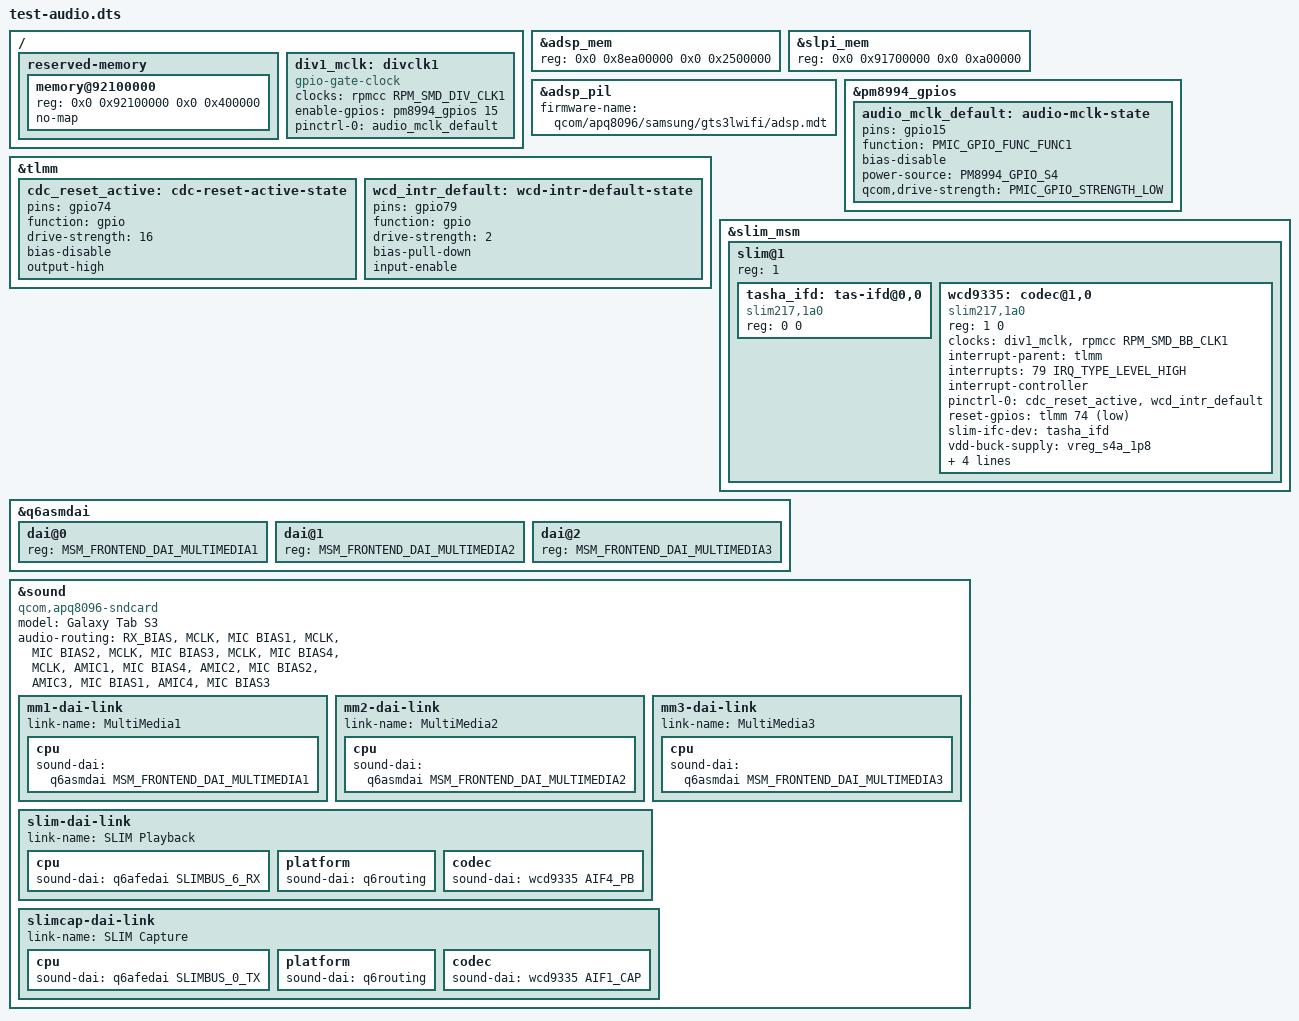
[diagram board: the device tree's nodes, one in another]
// SPDX-License-Identifier: BSD-3-Clause
/*
 * Audio test, stage 1: ADSP + WCD9335 (headphones and microphones).
 * Built on the Venus test DT.
 *
 * - ADSP: Samsung's signed firmware from the modem partition
 *   (image/adsp.mdt + .b00-.b09, ADSP.8996.2.7.1.C1-00013). Its segments are
 *   relocatable and span 0x2100000 bytes, more than msm8996.dtsi's 27 MB
 *   adsp_mem, so adsp_mem grows to the start of gpu_mem. SLPI (unused for
 *   now) moves into the stock peripheral_region tail at 0x91700000, which
 *   the board DTS reserves.
 * - WCD9335 on SLIMbus like apq8096-db820c / msm8996-xiaomi-common, with the
 *   Samsung wiring from the stock DT: reset TLMM 74 (wcd_gpio_ctrl
 *   qcom,cdc-rst-n-gpio), interrupt TLMM 79 (wcd9xxx-irq gpio-connect, one
 *   line), MCLK 9.6 MHz from PM8994 GPIO 15 function 1 (audio-ref-clk,
 *   RPM div_clk1), all supplies PM8994 S4 1.8 V.
 * - Speakers sit behind four Richtek RT5508 amplifiers on I2S (stage 2).
 */

#include <dt-bindings/sound/qcom,q6afe.h>
#include <dt-bindings/sound/qcom,q6asm.h>
#include <dt-bindings/sound/qcom,wcd9335.h>
#include "test-venus.dts"

/ {
	reserved-memory {
		/delete-node/ memory@91700000;

		/* rest of the stock peripheral_region after slpi_mem */
		memory@92100000 {
			reg = <0x0 0x92100000 0x0 0x400000>;
			no-map;
		};
	};

	div1_mclk: divclk1 {
		compatible = "gpio-gate-clock";
		clocks = <&rpmcc RPM_SMD_DIV_CLK1>;
		#clock-cells = <0>;
		enable-gpios = <&pm8994_gpios 15 GPIO_ACTIVE_HIGH>;
		pinctrl-names = "default";
		pinctrl-0 = <&audio_mclk_default>;
	};
};

&adsp_mem {
	reg = <0x0 0x8ea00000 0x0 0x2500000>;
};

&slpi_mem {
	reg = <0x0 0x91700000 0x0 0xa00000>;
};

&adsp_pil {
	firmware-name = "qcom/apq8096/samsung/gts3lwifi/adsp.mdt";
	status = "okay";
};

&pm8994_gpios {
	audio_mclk_default: audio-mclk-state {
		pins = "gpio15";
		function = PMIC_GPIO_FUNC_FUNC1;
		bias-disable;
		power-source = <PM8994_GPIO_S4>;
		qcom,drive-strength = <PMIC_GPIO_STRENGTH_LOW>;
	};
};

&tlmm {
	cdc_reset_active: cdc-reset-active-state {
		pins = "gpio74";
		function = "gpio";
		drive-strength = <16>;
		bias-disable;
		output-high;
	};

	wcd_intr_default: wcd-intr-default-state {
		pins = "gpio79";
		function = "gpio";
		drive-strength = <2>;
		bias-pull-down;
		input-enable;
	};
};

&slim_msm {
	status = "okay";

	slim@1 {
		reg = <1>;
		#address-cells = <2>;
		#size-cells = <0>;

		tasha_ifd: tas-ifd@0,0 {
			compatible = "slim217,1a0";
			reg = <0 0>;
		};

		wcd9335: codec@1,0 {
			compatible = "slim217,1a0";
			reg = <1 0>;

			clock-names = "mclk", "slimbus";
			clocks = <&div1_mclk>,
				 <&rpmcc RPM_SMD_BB_CLK1>;
			interrupt-parent = <&tlmm>;
			interrupts = <79 IRQ_TYPE_LEVEL_HIGH>;
			interrupt-names = "intr1";
			interrupt-controller;
			#interrupt-cells = <1>;

			pinctrl-0 = <&cdc_reset_active &wcd_intr_default>;
			pinctrl-names = "default";

			reset-gpios = <&tlmm 74 GPIO_ACTIVE_LOW>;
			slim-ifc-dev = <&tasha_ifd>;

			#sound-dai-cells = <1>;

			vdd-buck-supply = <&vreg_s4a_1p8>;
			vdd-buck-sido-supply = <&vreg_s4a_1p8>;
			vdd-tx-supply = <&vreg_s4a_1p8>;
			vdd-rx-supply = <&vreg_s4a_1p8>;
			vdd-io-supply = <&vreg_s4a_1p8>;
		};
	};
};

&q6asmdai {
	dai@0 {
		reg = <MSM_FRONTEND_DAI_MULTIMEDIA1>;
	};

	dai@1 {
		reg = <MSM_FRONTEND_DAI_MULTIMEDIA2>;
	};

	dai@2 {
		reg = <MSM_FRONTEND_DAI_MULTIMEDIA3>;
	};
};

&sound {
	compatible = "qcom,apq8096-sndcard";
	model = "Galaxy Tab S3";
	/*
	 * Stock routing: AMIC1 <- MIC BIAS4 (third mic), AMIC2 <- MIC BIAS2
	 * (headset mic), AMIC3 <- MIC BIAS1 (main mic), AMIC4 <- MIC BIAS3.
	 * In the wcd9335 driver only the RX DACs (via RX_BIAS) pull in MCLK,
	 * so a capture without a playback stream records digital silence.
	 * Hang the mic biases on MCLK as well.
	 */
	audio-routing = "RX_BIAS", "MCLK",
			"MIC BIAS1", "MCLK",
			"MIC BIAS2", "MCLK",
			"MIC BIAS3", "MCLK",
			"MIC BIAS4", "MCLK",
			"AMIC1", "MIC BIAS4",
			"AMIC2", "MIC BIAS2",
			"AMIC3", "MIC BIAS1",
			"AMIC4", "MIC BIAS3";

	mm1-dai-link {
		link-name = "MultiMedia1";
		cpu {
			sound-dai = <&q6asmdai MSM_FRONTEND_DAI_MULTIMEDIA1>;
		};
	};

	mm2-dai-link {
		link-name = "MultiMedia2";
		cpu {
			sound-dai = <&q6asmdai MSM_FRONTEND_DAI_MULTIMEDIA2>;
		};
	};

	mm3-dai-link {
		link-name = "MultiMedia3";
		cpu {
			sound-dai = <&q6asmdai MSM_FRONTEND_DAI_MULTIMEDIA3>;
		};
	};

	slim-dai-link {
		link-name = "SLIM Playback";
		cpu {
			sound-dai = <&q6afedai SLIMBUS_6_RX>;
		};

		platform {
			sound-dai = <&q6routing>;
		};

		codec {
			sound-dai = <&wcd9335 AIF4_PB>;
		};
	};

	slimcap-dai-link {
		link-name = "SLIM Capture";
		cpu {
			sound-dai = <&q6afedai SLIMBUS_0_TX>;
		};

		platform {
			sound-dai = <&q6routing>;
		};

		codec {
			sound-dai = <&wcd9335 AIF1_CAP>;
		};
	};
};
